# nrf5340_network register map
Vendor: Nordic Semiconductor; Series: nrf53; File version: 1
CPU: CM33 r0p4, little endian, MPU, no FPU, 3 interrupt priority bits, 30 interrupts
Registers are 32-bit, read-write, reset 0x0 unless marked. A register's access mark holds for its fields unless they carry their own. Offsets are from the block's base; [hi:lo] are bit positions; lines under a group give offsets from that group; {n}, {i} and the like mark numbered series; 'fields as' and 'values as' point back to an identical list.

## RADIO_NS — 2.4 GHz radio
Base 0x41008000
0x00 TASKS_TXEN wo — Enable RADIO in TX mode
  [0] TASKS_TXEN
    1=Trigger task
0x04 TASKS_RXEN wo — Enable RADIO in RX mode
  [0] TASKS_RXEN
    1=Trigger task
0x08 TASKS_START wo — Start RADIO
  [0] TASKS_START
    1=Trigger task
0x0C TASKS_STOP wo — Stop RADIO
  [0] TASKS_STOP
    1=Trigger task
0x10 TASKS_DISABLE wo — Disable RADIO
  [0] TASKS_DISABLE
    1=Trigger task
0x14 TASKS_RSSISTART wo — Start the RSSI and take one single sample of the receive signal strength
  [0] TASKS_RSSISTART
    1=Trigger task
0x18 TASKS_RSSISTOP wo — Stop the RSSI measurement
  [0] TASKS_RSSISTOP
    1=Trigger task
0x1C TASKS_BCSTART wo — Start the bit counter
  [0] TASKS_BCSTART
    1=Trigger task
0x20 TASKS_BCSTOP wo — Stop the bit counter
  [0] TASKS_BCSTOP
    1=Trigger task
0x24 TASKS_EDSTART wo — Start the energy detect measurement used in IEEE 802.15.4 mode
  [0] TASKS_EDSTART
    1=Trigger task
0x28 TASKS_EDSTOP wo — Stop the energy detect measurement
  [0] TASKS_EDSTOP
    1=Trigger task
0x2C TASKS_CCASTART wo — Start the clear channel assessment used in IEEE 802.15.4 mode
  [0] TASKS_CCASTART
    1=Trigger task
0x30 TASKS_CCASTOP wo — Stop the clear channel assessment
  [0] TASKS_CCASTOP
    1=Trigger task
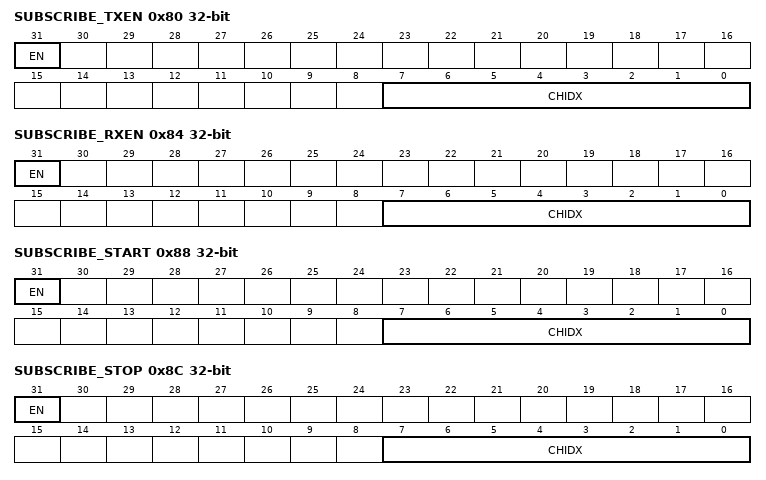
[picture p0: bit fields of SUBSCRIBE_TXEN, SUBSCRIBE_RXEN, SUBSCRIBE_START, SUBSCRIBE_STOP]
0x80 SUBSCRIBE_TXEN — Subscribe configuration for task TXEN
  [31] EN
    0=Disabled (Disable subscription); 1=Enabled (Enable subscription)
  [7:0] CHIDX — DPPI channel that task TXEN will subscribe to
0x84 SUBSCRIBE_RXEN — Subscribe configuration for task RXEN
  [31] EN
    values as SUBSCRIBE_TXEN.EN
  [7:0] CHIDX — DPPI channel that task RXEN will subscribe to
0x88 SUBSCRIBE_START — Subscribe configuration for task START
  [31] EN
    values as SUBSCRIBE_TXEN.EN
  [7:0] CHIDX — DPPI channel that task START will subscribe to
0x8C SUBSCRIBE_STOP — Subscribe configuration for task STOP
  [31] EN
    values as SUBSCRIBE_TXEN.EN
  [7:0] CHIDX — DPPI channel that task STOP will subscribe to
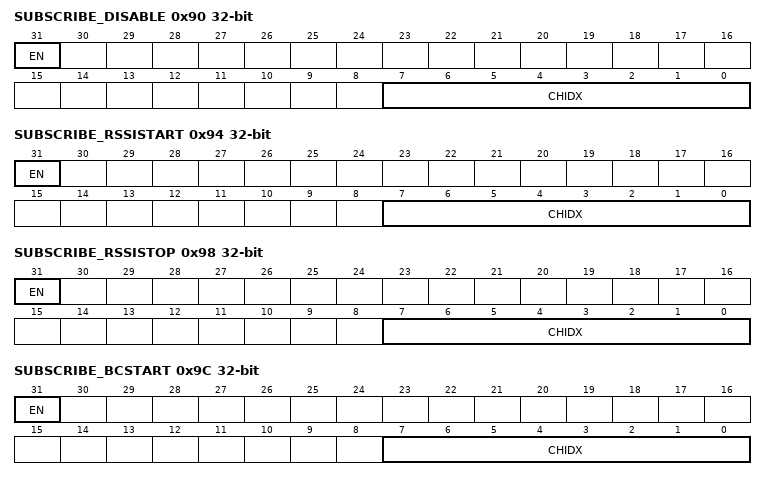
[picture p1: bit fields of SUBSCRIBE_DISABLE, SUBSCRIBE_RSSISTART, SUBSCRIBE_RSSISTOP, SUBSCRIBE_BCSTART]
0x90 SUBSCRIBE_DISABLE — Subscribe configuration for task DISABLE
  [31] EN
    values as SUBSCRIBE_TXEN.EN
  [7:0] CHIDX — DPPI channel that task DISABLE will subscribe to
0x94 SUBSCRIBE_RSSISTART — Subscribe configuration for task RSSISTART
  [31] EN
    values as SUBSCRIBE_TXEN.EN
  [7:0] CHIDX — DPPI channel that task RSSISTART will subscribe to
0x98 SUBSCRIBE_RSSISTOP — Subscribe configuration for task RSSISTOP
  [31] EN
    values as SUBSCRIBE_TXEN.EN
  [7:0] CHIDX — DPPI channel that task RSSISTOP will subscribe to
0x9C SUBSCRIBE_BCSTART — Subscribe configuration for task BCSTART
  [31] EN
    values as SUBSCRIBE_TXEN.EN
  [7:0] CHIDX — DPPI channel that task BCSTART will subscribe to
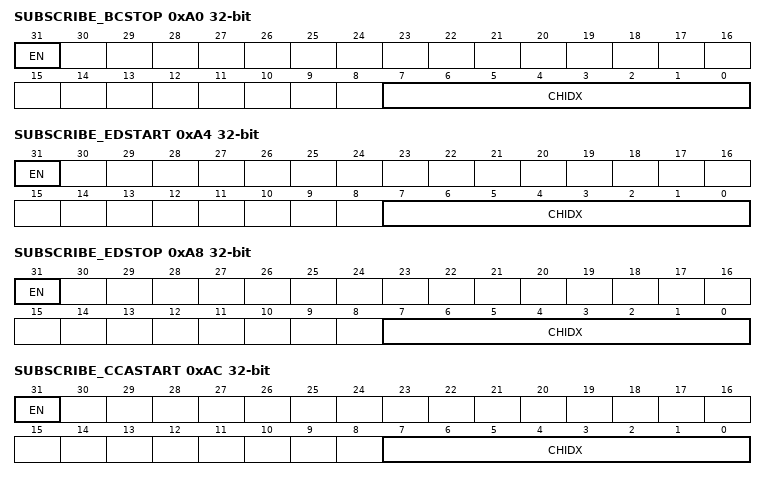
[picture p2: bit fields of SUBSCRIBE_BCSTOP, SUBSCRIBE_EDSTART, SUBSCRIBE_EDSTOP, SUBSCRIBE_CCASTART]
0xA0 SUBSCRIBE_BCSTOP — Subscribe configuration for task BCSTOP
  [31] EN
    values as SUBSCRIBE_TXEN.EN
  [7:0] CHIDX — DPPI channel that task BCSTOP will subscribe to
0xA4 SUBSCRIBE_EDSTART — Subscribe configuration for task EDSTART
  [31] EN
    values as SUBSCRIBE_TXEN.EN
  [7:0] CHIDX — DPPI channel that task EDSTART will subscribe to
0xA8 SUBSCRIBE_EDSTOP — Subscribe configuration for task EDSTOP
  [31] EN
    values as SUBSCRIBE_TXEN.EN
  [7:0] CHIDX — DPPI channel that task EDSTOP will subscribe to
0xAC SUBSCRIBE_CCASTART — Subscribe configuration for task CCASTART
  [31] EN
    values as SUBSCRIBE_TXEN.EN
  [7:0] CHIDX — DPPI channel that task CCASTART will subscribe to
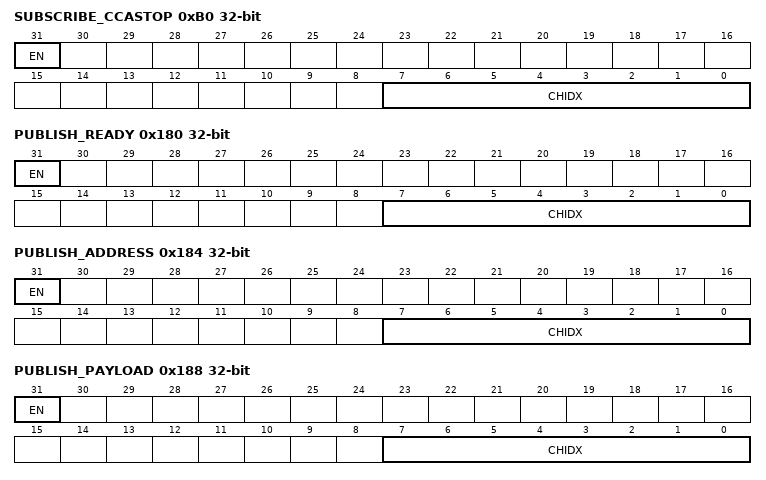
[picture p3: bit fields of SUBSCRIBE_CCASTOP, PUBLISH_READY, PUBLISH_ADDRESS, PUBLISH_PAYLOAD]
0xB0 SUBSCRIBE_CCASTOP — Subscribe configuration for task CCASTOP
  [31] EN
    values as SUBSCRIBE_TXEN.EN
  [7:0] CHIDX — DPPI channel that task CCASTOP will subscribe to
0x100 EVENTS_READY — RADIO has ramped up and is ready to be started
  [0] EVENTS_READY
    0=NotGenerated (Event not generated); 1=Generated (Event generated)
0x104 EVENTS_ADDRESS — Address sent or received
  [0] EVENTS_ADDRESS
    values as EVENTS_READY.EVENTS_READY
0x108 EVENTS_PAYLOAD — Packet payload sent or received
  [0] EVENTS_PAYLOAD
    values as EVENTS_READY.EVENTS_READY
0x10C EVENTS_END — Packet sent or received
  [0] EVENTS_END
    values as EVENTS_READY.EVENTS_READY
0x110 EVENTS_DISABLED — RADIO has been disabled
  [0] EVENTS_DISABLED
    values as EVENTS_READY.EVENTS_READY
0x114 EVENTS_DEVMATCH — A device address match occurred on the last received packet
  [0] EVENTS_DEVMATCH
    values as EVENTS_READY.EVENTS_READY
0x118 EVENTS_DEVMISS — No device address match occurred on the last received packet
  [0] EVENTS_DEVMISS
    values as EVENTS_READY.EVENTS_READY
0x11C EVENTS_RSSIEND — Sampling of receive signal strength complete
  [0] EVENTS_RSSIEND
    values as EVENTS_READY.EVENTS_READY
0x128 EVENTS_BCMATCH — Bit counter reached bit count value
  [0] EVENTS_BCMATCH
    values as EVENTS_READY.EVENTS_READY
0x130 EVENTS_CRCOK — Packet received with CRC ok
  [0] EVENTS_CRCOK
    values as EVENTS_READY.EVENTS_READY
0x134 EVENTS_CRCERROR — Packet received with CRC error
  [0] EVENTS_CRCERROR
    values as EVENTS_READY.EVENTS_READY
0x138 EVENTS_FRAMESTART — IEEE 802.15.4 length field received
  [0] EVENTS_FRAMESTART
    values as EVENTS_READY.EVENTS_READY
0x13C EVENTS_EDEND — Sampling of energy detection complete. A new ED sample is ready for readout from the RADIO.EDSAMPLE register.
  [0] EVENTS_EDEND
    values as EVENTS_READY.EVENTS_READY
0x140 EVENTS_EDSTOPPED — The sampling of energy detection has stopped
  [0] EVENTS_EDSTOPPED
    values as EVENTS_READY.EVENTS_READY
0x144 EVENTS_CCAIDLE — Wireless medium in idle - clear to send
  [0] EVENTS_CCAIDLE
    values as EVENTS_READY.EVENTS_READY
0x148 EVENTS_CCABUSY — Wireless medium busy - do not send
  [0] EVENTS_CCABUSY
    values as EVENTS_READY.EVENTS_READY
0x14C EVENTS_CCASTOPPED — The CCA has stopped
  [0] EVENTS_CCASTOPPED
    values as EVENTS_READY.EVENTS_READY
0x150 EVENTS_RATEBOOST — Ble_LR CI field received, receive mode is changed from Ble_LR125Kbit to Ble_LR500Kbit.
  [0] EVENTS_RATEBOOST
    values as EVENTS_READY.EVENTS_READY
0x154 EVENTS_TXREADY — RADIO has ramped up and is ready to be started TX path
  [0] EVENTS_TXREADY
    values as EVENTS_READY.EVENTS_READY
0x158 EVENTS_RXREADY — RADIO has ramped up and is ready to be started RX path
  [0] EVENTS_RXREADY
    values as EVENTS_READY.EVENTS_READY
0x15C EVENTS_MHRMATCH — MAC header match found
  [0] EVENTS_MHRMATCH
    values as EVENTS_READY.EVENTS_READY
0x168 EVENTS_SYNC — Preamble indicator
  [0] EVENTS_SYNC
    values as EVENTS_READY.EVENTS_READY
0x16C EVENTS_PHYEND — Generated when last bit is sent on air, or received from air
  [0] EVENTS_PHYEND
    values as EVENTS_READY.EVENTS_READY
0x170 EVENTS_CTEPRESENT — CTE is present (early warning right after receiving CTEInfo byte)
  [0] EVENTS_CTEPRESENT
    values as EVENTS_READY.EVENTS_READY
0x180 PUBLISH_READY — Publish configuration for event READY
  [31] EN
    0=Disabled (Disable publishing); 1=Enabled (Enable publishing)
  [7:0] CHIDX — DPPI channel that event READY will publish to.
0x184 PUBLISH_ADDRESS — Publish configuration for event ADDRESS
  [31] EN
    values as PUBLISH_READY.EN
  [7:0] CHIDX — DPPI channel that event ADDRESS will publish to.
0x188 PUBLISH_PAYLOAD — Publish configuration for event PAYLOAD
  [31] EN
    values as PUBLISH_READY.EN
  [7:0] CHIDX — DPPI channel that event PAYLOAD will publish to.
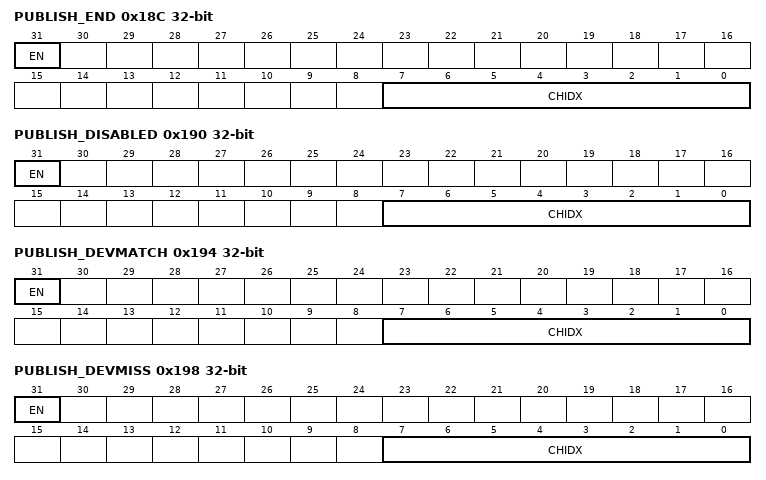
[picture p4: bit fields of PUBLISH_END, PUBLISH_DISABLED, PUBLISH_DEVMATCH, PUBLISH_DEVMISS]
0x18C PUBLISH_END — Publish configuration for event END
  [31] EN
    values as PUBLISH_READY.EN
  [7:0] CHIDX — DPPI channel that event END will publish to.
0x190 PUBLISH_DISABLED — Publish configuration for event DISABLED
  [31] EN
    values as PUBLISH_READY.EN
  [7:0] CHIDX — DPPI channel that event DISABLED will publish to.
0x194 PUBLISH_DEVMATCH — Publish configuration for event DEVMATCH
  [31] EN
    values as PUBLISH_READY.EN
  [7:0] CHIDX — DPPI channel that event DEVMATCH will publish to.
0x198 PUBLISH_DEVMISS — Publish configuration for event DEVMISS
  [31] EN
    values as PUBLISH_READY.EN
  [7:0] CHIDX — DPPI channel that event DEVMISS will publish to.
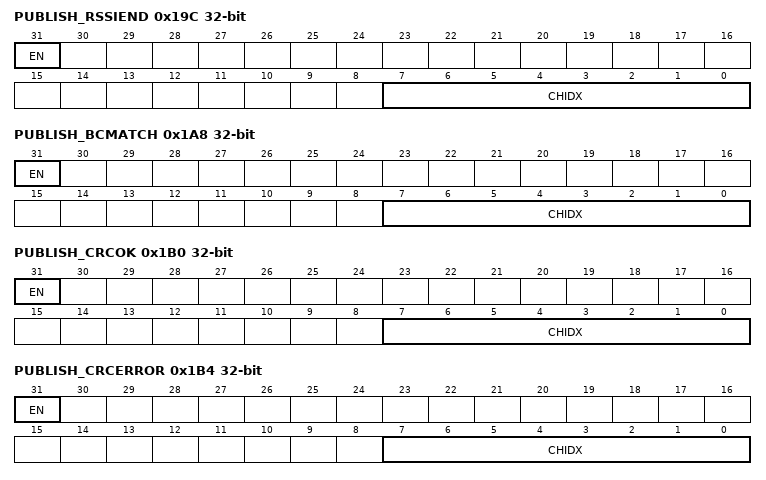
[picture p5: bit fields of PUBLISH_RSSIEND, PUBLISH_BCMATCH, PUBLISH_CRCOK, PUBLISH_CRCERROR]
0x19C PUBLISH_RSSIEND — Publish configuration for event RSSIEND
  [31] EN
    values as PUBLISH_READY.EN
  [7:0] CHIDX — DPPI channel that event RSSIEND will publish to.
0x1A8 PUBLISH_BCMATCH — Publish configuration for event BCMATCH
  [31] EN
    values as PUBLISH_READY.EN
  [7:0] CHIDX — DPPI channel that event BCMATCH will publish to.
0x1B0 PUBLISH_CRCOK — Publish configuration for event CRCOK
  [31] EN
    values as PUBLISH_READY.EN
  [7:0] CHIDX — DPPI channel that event CRCOK will publish to.
0x1B4 PUBLISH_CRCERROR — Publish configuration for event CRCERROR
  [31] EN
    values as PUBLISH_READY.EN
  [7:0] CHIDX — DPPI channel that event CRCERROR will publish to.
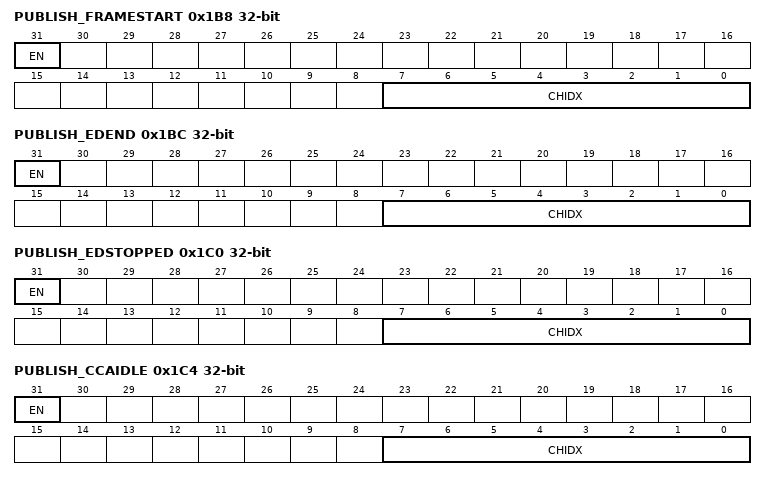
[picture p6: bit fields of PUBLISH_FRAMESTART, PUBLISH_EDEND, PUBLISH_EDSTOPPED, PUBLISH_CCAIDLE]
0x1B8 PUBLISH_FRAMESTART — Publish configuration for event FRAMESTART
  [31] EN
    values as PUBLISH_READY.EN
  [7:0] CHIDX — DPPI channel that event FRAMESTART will publish to.
0x1BC PUBLISH_EDEND — Publish configuration for event EDEND
  [31] EN
    values as PUBLISH_READY.EN
  [7:0] CHIDX — DPPI channel that event EDEND will publish to.
0x1C0 PUBLISH_EDSTOPPED — Publish configuration for event EDSTOPPED
  [31] EN
    values as PUBLISH_READY.EN
  [7:0] CHIDX — DPPI channel that event EDSTOPPED will publish to.
0x1C4 PUBLISH_CCAIDLE — Publish configuration for event CCAIDLE
  [31] EN
    values as PUBLISH_READY.EN
  [7:0] CHIDX — DPPI channel that event CCAIDLE will publish to.
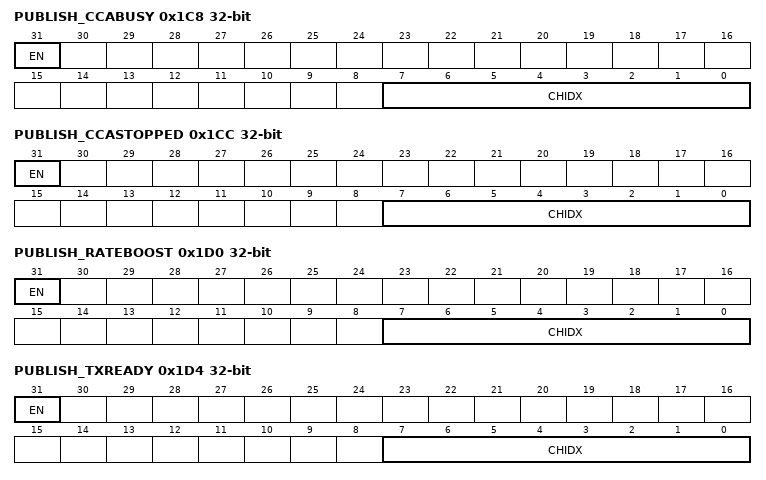
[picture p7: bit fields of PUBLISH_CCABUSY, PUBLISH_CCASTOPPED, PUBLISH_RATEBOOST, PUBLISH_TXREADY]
0x1C8 PUBLISH_CCABUSY — Publish configuration for event CCABUSY
  [31] EN
    values as PUBLISH_READY.EN
  [7:0] CHIDX — DPPI channel that event CCABUSY will publish to.
0x1CC PUBLISH_CCASTOPPED — Publish configuration for event CCASTOPPED
  [31] EN
    values as PUBLISH_READY.EN
  [7:0] CHIDX — DPPI channel that event CCASTOPPED will publish to.
0x1D0 PUBLISH_RATEBOOST — Publish configuration for event RATEBOOST
  [31] EN
    values as PUBLISH_READY.EN
  [7:0] CHIDX — DPPI channel that event RATEBOOST will publish to.
0x1D4 PUBLISH_TXREADY — Publish configuration for event TXREADY
  [31] EN
    values as PUBLISH_READY.EN
  [7:0] CHIDX — DPPI channel that event TXREADY will publish to.
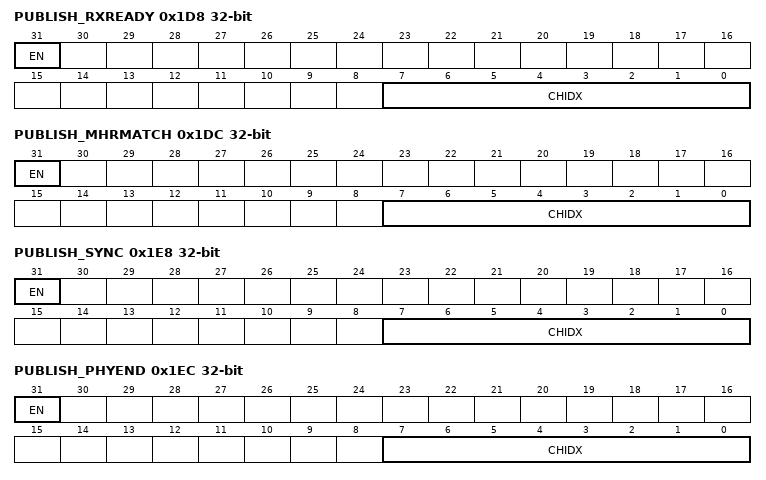
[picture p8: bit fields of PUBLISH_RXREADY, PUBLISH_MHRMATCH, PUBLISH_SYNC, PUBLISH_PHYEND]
0x1D8 PUBLISH_RXREADY — Publish configuration for event RXREADY
  [31] EN
    values as PUBLISH_READY.EN
  [7:0] CHIDX — DPPI channel that event RXREADY will publish to.
0x1DC PUBLISH_MHRMATCH — Publish configuration for event MHRMATCH
  [31] EN
    values as PUBLISH_READY.EN
  [7:0] CHIDX — DPPI channel that event MHRMATCH will publish to.
0x1E8 PUBLISH_SYNC — Publish configuration for event SYNC
  [31] EN
    values as PUBLISH_READY.EN
  [7:0] CHIDX — DPPI channel that event SYNC will publish to.
0x1EC PUBLISH_PHYEND — Publish configuration for event PHYEND
  [31] EN
    values as PUBLISH_READY.EN
  [7:0] CHIDX — DPPI channel that event PHYEND will publish to.
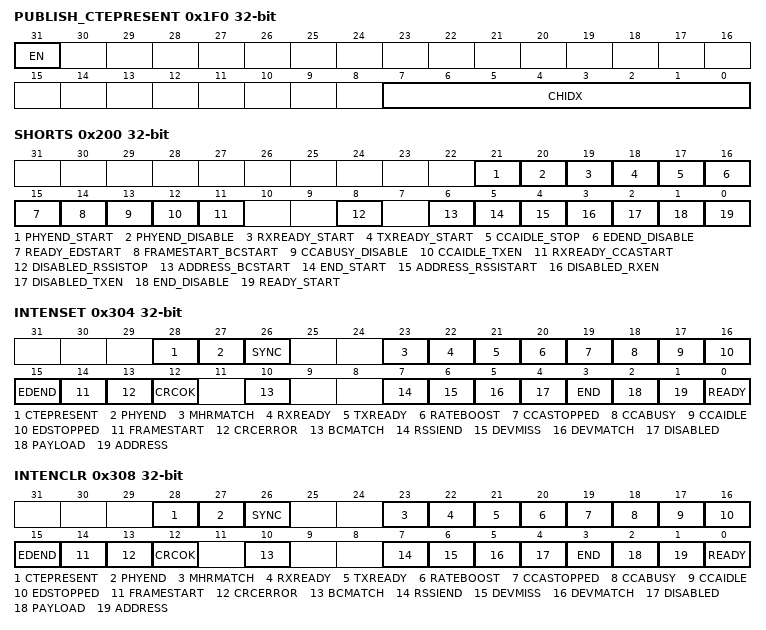
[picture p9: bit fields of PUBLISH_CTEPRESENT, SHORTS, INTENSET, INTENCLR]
0x1F0 PUBLISH_CTEPRESENT — Publish configuration for event CTEPRESENT
  [31] EN
    values as PUBLISH_READY.EN
  [7:0] CHIDX — DPPI channel that event CTEPRESENT will publish to.
0x200 SHORTS — Shortcuts between local events and tasks
  [all] fields
    0=Disabled (Disable shortcut); 1=Enabled (Enable shortcut)
  [21] PHYEND_START — Shortcut between event PHYEND and task START
  [20] PHYEND_DISABLE — Shortcut between event PHYEND and task DISABLE
  [19] RXREADY_START — Shortcut between event RXREADY and task START
  [18] TXREADY_START — Shortcut between event TXREADY and task START
  [17] CCAIDLE_STOP — Shortcut between event CCAIDLE and task STOP
  [16] EDEND_DISABLE — Shortcut between event EDEND and task DISABLE
  [15] READY_EDSTART — Shortcut between event READY and task EDSTART
  [14] FRAMESTART_BCSTART — Shortcut between event FRAMESTART and task BCSTART
  [13] CCABUSY_DISABLE — Shortcut between event CCABUSY and task DISABLE
  [12] CCAIDLE_TXEN — Shortcut between event CCAIDLE and task TXEN
  [11] RXREADY_CCASTART — Shortcut between event RXREADY and task CCASTART
  [8] DISABLED_RSSISTOP — Shortcut between event DISABLED and task RSSISTOP
  [6] ADDRESS_BCSTART — Shortcut between event ADDRESS and task BCSTART
  [5] END_START — Shortcut between event END and task START
  [4] ADDRESS_RSSISTART — Shortcut between event ADDRESS and task RSSISTART
  [3] DISABLED_RXEN — Shortcut between event DISABLED and task RXEN
  [2] DISABLED_TXEN — Shortcut between event DISABLED and task TXEN
  [1] END_DISABLE — Shortcut between event END and task DISABLE
  [0] READY_START — Shortcut between event READY and task START
0x304 INTENSET — Enable interrupt
  [all] fields
    on read: 0=Disabled (Read: Disabled); 1=Enabled (Read: Enabled) | on write: 1=Set (Enable)
  [28] CTEPRESENT — Write '1' to enable interrupt for event CTEPRESENT
  [27] PHYEND — Write '1' to enable interrupt for event PHYEND
  [26] SYNC — Write '1' to enable interrupt for event SYNC
  [23] MHRMATCH — Write '1' to enable interrupt for event MHRMATCH
  [22] RXREADY — Write '1' to enable interrupt for event RXREADY
  [21] TXREADY — Write '1' to enable interrupt for event TXREADY
  [20] RATEBOOST — Write '1' to enable interrupt for event RATEBOOST
  [19] CCASTOPPED — Write '1' to enable interrupt for event CCASTOPPED
  [18] CCABUSY — Write '1' to enable interrupt for event CCABUSY
  [17] CCAIDLE — Write '1' to enable interrupt for event CCAIDLE
  [16] EDSTOPPED — Write '1' to enable interrupt for event EDSTOPPED
  [15] EDEND — Write '1' to enable interrupt for event EDEND
  [14] FRAMESTART — Write '1' to enable interrupt for event FRAMESTART
  [13] CRCERROR — Write '1' to enable interrupt for event CRCERROR
  [12] CRCOK — Write '1' to enable interrupt for event CRCOK
  [10] BCMATCH — Write '1' to enable interrupt for event BCMATCH
  [7] RSSIEND — Write '1' to enable interrupt for event RSSIEND
  [6] DEVMISS — Write '1' to enable interrupt for event DEVMISS
  [5] DEVMATCH — Write '1' to enable interrupt for event DEVMATCH
  [4] DISABLED — Write '1' to enable interrupt for event DISABLED
  [3] END — Write '1' to enable interrupt for event END
  [2] PAYLOAD — Write '1' to enable interrupt for event PAYLOAD
  [1] ADDRESS — Write '1' to enable interrupt for event ADDRESS
  [0] READY — Write '1' to enable interrupt for event READY
0x308 INTENCLR — Disable interrupt
  [all] fields
    on read: 0=Disabled (Read: Disabled); 1=Enabled (Read: Enabled) | on write: 1=Clear (Disable)
  [28] CTEPRESENT — Write '1' to disable interrupt for event CTEPRESENT
  [27] PHYEND — Write '1' to disable interrupt for event PHYEND
  [26] SYNC — Write '1' to disable interrupt for event SYNC
  [23] MHRMATCH — Write '1' to disable interrupt for event MHRMATCH
  [22] RXREADY — Write '1' to disable interrupt for event RXREADY
  [21] TXREADY — Write '1' to disable interrupt for event TXREADY
  [20] RATEBOOST — Write '1' to disable interrupt for event RATEBOOST
  [19] CCASTOPPED — Write '1' to disable interrupt for event CCASTOPPED
  [18] CCABUSY — Write '1' to disable interrupt for event CCABUSY
  [17] CCAIDLE — Write '1' to disable interrupt for event CCAIDLE
  [16] EDSTOPPED — Write '1' to disable interrupt for event EDSTOPPED
  [15] EDEND — Write '1' to disable interrupt for event EDEND
  [14] FRAMESTART — Write '1' to disable interrupt for event FRAMESTART
  [13] CRCERROR — Write '1' to disable interrupt for event CRCERROR
  [12] CRCOK — Write '1' to disable interrupt for event CRCOK
  [10] BCMATCH — Write '1' to disable interrupt for event BCMATCH
  [7] RSSIEND — Write '1' to disable interrupt for event RSSIEND
  [6] DEVMISS — Write '1' to disable interrupt for event DEVMISS
  [5] DEVMATCH — Write '1' to disable interrupt for event DEVMATCH
  [4] DISABLED — Write '1' to disable interrupt for event DISABLED
  [3] END — Write '1' to disable interrupt for event END
  [2] PAYLOAD — Write '1' to disable interrupt for event PAYLOAD
  [1] ADDRESS — Write '1' to disable interrupt for event ADDRESS
  [0] READY — Write '1' to disable interrupt for event READY
0x400 CRCSTATUS ro
  [0] CRCSTATUS — CRC status of packet received
    0=CRCError (Packet received with CRC error); 1=CRCOk (Packet received with CRC ok)
0x408 RXMATCH ro — Received address
  [2:0] RXMATCH
0x40C RXCRC ro — CRC field of previously received packet
  [23:0] RXCRC
0x410 DAI ro — Device address match index
  [2:0] DAI
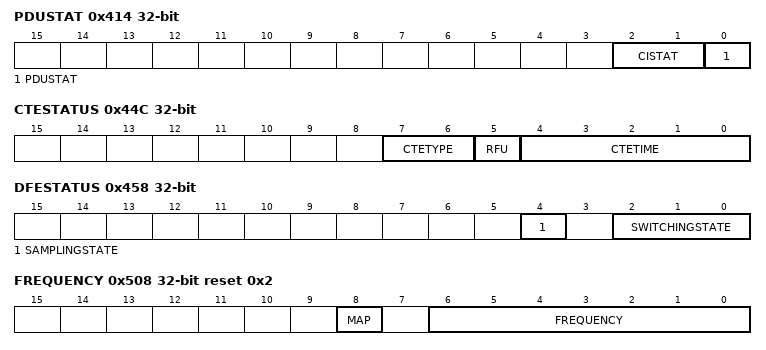
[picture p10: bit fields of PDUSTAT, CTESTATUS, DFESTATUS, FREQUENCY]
0x414 PDUSTAT ro — Payload status
  [2:1] CISTAT — Status on what rate packet is received with in Long Range
    0=LR125kbit (Frame is received at 125 kbps); 1=LR500kbit (Frame is received at 500 kbps)
  [0] PDUSTAT — Status on payload length vs. PCNF1.MAXLEN
    0=LessThan (Payload less than PCNF1.MAXLEN); 1=GreaterThan (Payload greater than PCNF1.MAXLEN)
0x44C CTESTATUS ro — CTEInfo parsed from received packet
  [7:6] CTETYPE — CTEType parsed from packet
  [5] RFU — RFU parsed from packet
  [4:0] CTETIME — CTETime parsed from packet
0x458 DFESTATUS ro — DFE status information
  [4] SAMPLINGSTATE — Internal state of sampling state machine
    0=Idle (Sampling state Idle); 1=Sampling state Sampling
  [2:0] SWITCHINGSTATE — Internal state of switching state machine
    0=Idle (Switching state Idle); 1=Offset (Switching state Offset); 2=Guard (Switching state Guard); 3=Ref (Switching state Ref); 4=Switching state Switching; 5=Ending (Switching state Ending)
0x504 PACKETPTR reset 0x1000000 — Packet pointer
0x508 FREQUENCY reset 0x2
  [8] MAP — Channel map selection
    0=Default (Channel map between 2400 MHz and 2500 MHz); 1=Low (Channel map between 2360 MHz and 2460 MHz)
  [6:0] FREQUENCY — Radio channel frequency
0x50C TXPOWER — Output power
  [7:0] TXPOWER — RADIO output power
    0=0dBm; 255=Neg1dBm (-1 dBm); 254=Neg2dBm (-2 dBm); 253=Neg3dBm (-3 dBm); 252=Neg4dBm (-4 dBm); 251=Neg5dBm (-5 dBm); 250=Neg6dBm (-6 dBm); 249=Neg7dBm (-7 dBm); 248=Neg8dBm (-8 dBm); 244=Neg12dBm (-12 dBm); 240=Neg16dBm (-16 dBm); 236=Neg20dBm (-20 dBm); 226=Neg30dBm (Deprecated enumerator - -40 dBm); 216=Neg40dBm (-40 dBm)
0x510 MODE — Data rate and modulation
  [3:0] MODE — Radio data rate and modulation setting. The radio supports frequency-shift keying (FSK) modulation.
    0=Nrf_1Mbit (1 Mbps Nordic proprietary radio mode); 1=Nrf_2Mbit (2 Mbps Nordic proprietary radio mode); 3=Ble_1Mbit (1 Mbps BLE); 4=Ble_2Mbit (2 Mbps BLE); 5=Ble_LR125Kbit (Long Range 125 kbps TX, 125 kbps and 500 kbps RX); 6=Ble_LR500Kbit (Long Range 500 kbps TX, 125 kbps and 500 kbps RX); 15=Ieee802154_250Kbit (IEEE 802.15.4-2006 250 kbps)
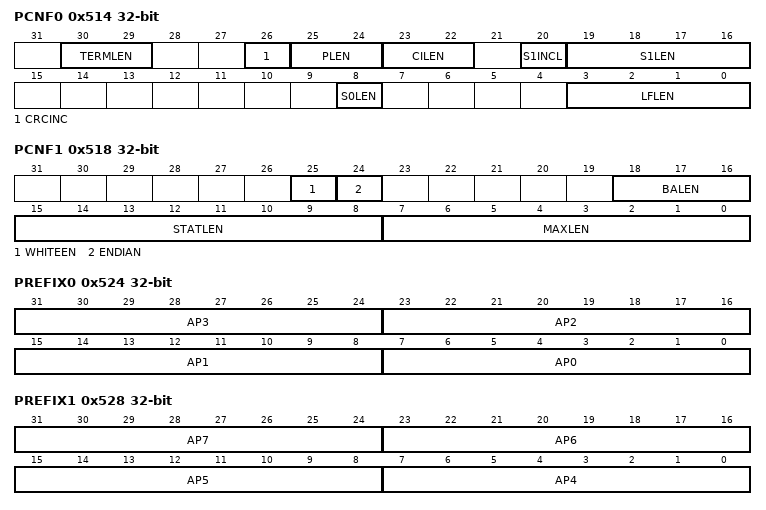
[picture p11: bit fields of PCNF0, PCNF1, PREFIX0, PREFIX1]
0x514 PCNF0 — Packet configuration register 0
  [30:29] TERMLEN — Length of TERM field in Long Range operation
  [26] CRCINC — Indicates if LENGTH field contains CRC or not
    0=Exclude (LENGTH does not contain CRC); 1=Include (LENGTH includes CRC)
  [25:24] PLEN — Length of preamble on air. Decision point: TASKS_START task
    0=8-bit preamble; 1=16-bit preamble; 2=32-bit zero preamble - used for IEEE 802.15.4; 3=LongRange (Preamble - used for Bluetooth LE Long Range)
  [23:22] CILEN — Length of code indicator - Long Range
  [20] S1INCL — Include or exclude S1 field in RAM
    0=Automatic (Include S1 field in RAM only if S1LEN > 0); 1=Include (Always include S1 field in RAM independent of S1LEN)
  [19:16] S1LEN — Length on air of S1 field in number of bits
  [8] S0LEN — Length on air of S0 field in number of bytes
  [3:0] LFLEN — Length on air of LENGTH field in number of bits
0x518 PCNF1 — Packet configuration register 1
  [25] WHITEEN — Enable or disable packet whitening
    0=Disabled; 1=Enabled
  [24] ENDIAN — On-air endianness of packet, this applies to the S0, LENGTH, S1, and the PAYLOAD fields.
    0=Little (Least significant bit on air first); 1=Big (Most significant bit on air first)
  [18:16] BALEN — Base address length in number of bytes
  [15:8] STATLEN — Static length in number of bytes
  [7:0] MAXLEN — Maximum length of packet payload. If the packet payload is larger than MAXLEN, the radio will truncate the payload to MAXLEN.
0x51C BASE0 — Base address 0
0x520 BASE1 — Base address 1
0x524 PREFIX0 — Prefixes bytes for logical addresses 0-3
  [8n+7:8n] AP{n} (n=0..3) — Address prefix {n}.
0x528 PREFIX1 — Prefixes bytes for logical addresses 4-7
  [8n-25:8n-32] AP{n} (n=4..7) — Address prefix {n}.
0x52C TXADDRESS — Transmit address select
  [2:0] TXADDRESS
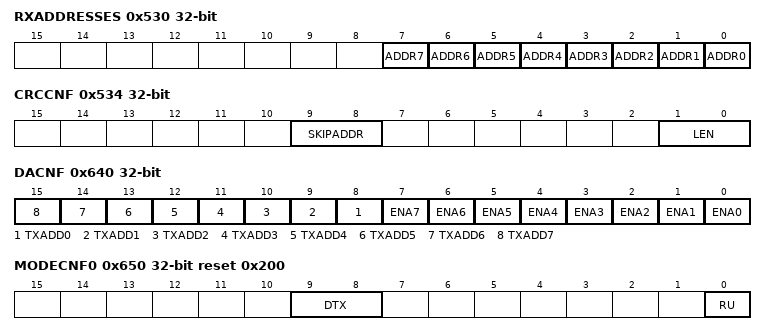
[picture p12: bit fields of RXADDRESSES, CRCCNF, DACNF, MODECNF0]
0x530 RXADDRESSES — Receive address select
  [all] fields
    0=Disabled; 1=Enabled
  [n] ADDR{n} (n=0..7) — Enable or disable reception on logical address {n}.
0x534 CRCCNF — CRC configuration
  [9:8] SKIPADDR — Include or exclude packet address field out of CRC calculation.
    0=Include (CRC calculation includes address field); 1=Skip (CRC calculation does not include address field. The CRC calculation will start at the first byte after the address.); 2=Ieee802154 (CRC calculation as per 802.15.4 standard. Starting at first byte after length field.)
  [1:0] LEN — CRC length in number of bytes For MODE Ble_LR125Kbit and Ble_LR500Kbit, only LEN set to 3 is supported
    0=Disabled (CRC length is zero and CRC calculation is disabled); 1=One (CRC length is one byte and CRC calculation is enabled); 2=Two (CRC length is two bytes and CRC calculation is enabled); 3=Three (CRC length is three bytes and CRC calculation is enabled)
0x538 CRCPOLY — CRC polynomial
  [23:0] CRCPOLY
0x53C CRCINIT — CRC initial value
  [23:0] CRCINIT
0x544 TIFS — Interframe spacing in us
  [9:0] TIFS — Interframe spacing in us.
0x548 RSSISAMPLE ro
  [6:0] RSSISAMPLE
0x550 STATE ro — Current radio state
  [3:0] STATE
    0=Disabled (RADIO is in the Disabled state); 1=RxRu (RADIO is in the RXRU state); 2=RxIdle (RADIO is in the RXIDLE state); 3=Rx (RADIO is in the RX state); 4=RxDisable (RADIO is in the RXDISABLED state); 9=TxRu (RADIO is in the TXRU state); 10=TxIdle (RADIO is in the TXIDLE state); 11=Tx (RADIO is in the TX state); 12=TxDisable (RADIO is in the TXDISABLED state)
0x554 DATAWHITEIV reset 0x40 — Data whitening initial value
  [6:0] DATAWHITEIV — Data whitening initial value. Bit 6 is hardwired to '1', writing '0' to it has no effect, and it will always be read back and used by the device as '1'.
0x560 BCC — Bit counter compare
{0x600+4i} DAB[{i}] (i=0..7) — Description collection: Device address base segment n
  [31:0] DAB — Device address base segment n
{0x620+4i} DAP[{i}] (i=0..7) — Description collection: Device address prefix n
  [15:0] DAP — Device address prefix n
0x640 DACNF — Device address match configuration
  [n+8] TXADD{n} (n=0..7) — TxAdd for device address {n}
  [n] ENA{n} (n=0..7) — Enable or disable device address matching using device address {n}
    0=Disabled; 1=Enabled
0x644 MHRMATCHCONF — Search pattern configuration
0x648 MHRMATCHMAS — Pattern mask
0x650 MODECNF0 reset 0x200 — Radio mode configuration register 0
  [9:8] DTX — Default TX value
    0=B1 (Transmit '1'); 1=B0 (Transmit '0'); 2=Center (Transmit center frequency)
  [0] RU — Radio ramp-up time
    0=Default ramp-up time (tRXEN and tTXEN), compatible with firmware written for nRF51; 1=Fast ramp-up (tRXEN,FAST and tTXEN,FAST), see electrical specifications for more information
0x660 SFD reset 0xA7 — IEEE 802.15.4 start of frame delimiter
  [7:0] SFD
0x664 EDCNT — IEEE 802.15.4 energy detect loop count
  [20:0] EDCNT
0x668 EDSAMPLE ro — IEEE 802.15.4 energy detect level
  [7:0] EDLVL
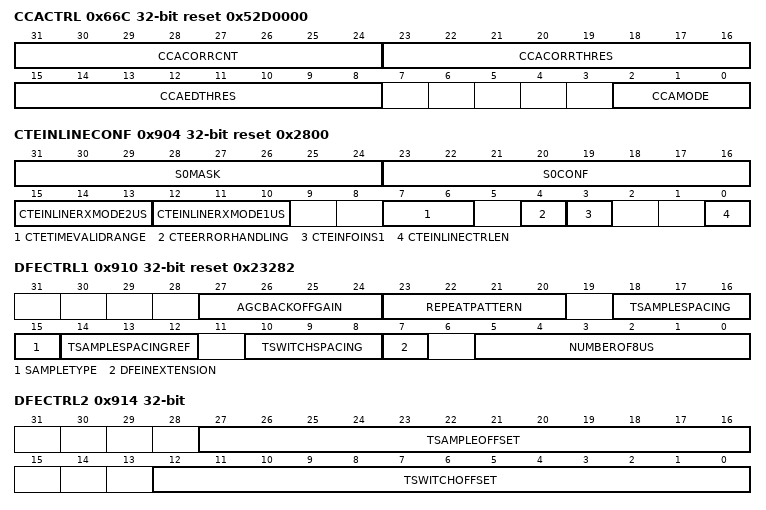
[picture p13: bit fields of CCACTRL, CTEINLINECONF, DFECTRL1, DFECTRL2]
0x66C CCACTRL reset 0x52D0000 — IEEE 802.15.4 clear channel assessment control
  [31:24] CCACORRCNT — Limit for occurances above CCACORRTHRES. When not equal to zero the corrolator based signal detect is enabled.
  [23:16] CCACORRTHRES — CCA correlator busy threshold. Only relevant to CarrierMode, CarrierAndEdMode, and CarrierOrEdMode.
  [15:8] CCAEDTHRES — CCA energy busy threshold. Used in all the CCA modes except CarrierMode.
  [2:0] CCAMODE — CCA mode of operation
    0=EdMode (Energy above threshold); 1=CarrierMode (Carrier seen); 2=CarrierAndEdMode (Energy above threshold AND carrier seen); 3=CarrierOrEdMode (Energy above threshold OR carrier seen); 4=EdModeTest1 (Energy above threshold test mode that will abort when first ED measurement over threshold is seen. No averaging.)
0x900 DFEMODE — Whether to use Angle-of-Arrival (AOA) or Angle-of-Departure (AOD)
  [1:0] DFEOPMODE — Direction finding operation mode
    0=Disabled (Direction finding mode disabled); 2=AoD (Direction finding mode set to AoD); 3=AoA (Direction finding mode set to AoA)
0x904 CTEINLINECONF reset 0x2800 — Configuration for CTE inline mode
  [31:24] S0MASK — S0 bit mask to set which bit to match
  [23:16] S0CONF — S0 bit pattern to match
  [15:13] CTEINLINERXMODE2US — Spacing between samples for the samples in the SWITCHING period when CTEINLINEMODE is set.
    1=4us; 2=2us; 3=1us; 4=500ns (0.5 us); 5=250ns (0.25 us); 6=125ns (0.125 us)
  [12:10] CTEINLINERXMODE1US — Spacing between samples for the samples in the SWITCHING period when CTEINLINEMODE is set.
    values as CTEINLINERXMODE2US
  [7:6] CTETIMEVALIDRANGE — Max range of CTETime
    0=20 in 8 us unit (default) Set to 20 if parsed CTETime is larger than 20; 1=31 in 8 us unit; 2=63 in 8 us unit
  [4] CTEERRORHANDLING — Sampling/switching if CRC is not OK
    1=Yes (Sampling and antenna switching also when CRC is not OK); 0=No (No sampling and antenna switching when CRC is not OK)
  [3] CTEINFOINS1 — CTEInfo is S1 byte or not
    1=InS1 (CTEInfo is in S1 byte (data PDU)); 0=NotInS1 (CTEInfo is NOT in S1 byte (advertising PDU))
  [0] CTEINLINECTRLEN — Enable parsing of CTEInfo from received packet in BLE modes
    1=Enabled (Parsing of CTEInfo is enabled); 0=Disabled (Parsing of CTEInfo is disabled)
0x910 DFECTRL1 reset 0x23282 — Various configuration for Direction finding
  [27:24] AGCBACKOFFGAIN — Gain will be lowered by the specified number of gain steps at the start of CTE
  [23:20] REPEATPATTERN — Repeat each individual antenna pattern N times sequentially, i.e. P0, P0, P1, P1, P2, P2, P3, P3, etc.
    0=NoRepeat (Do not repeat (1 time in total))
  [18:16] TSAMPLESPACING — Interval between samples in the SWITCHING period when CTEINLINECTRLEN is 0
    values as CTEINLINECONF.CTEINLINERXMODE2US
  [15] SAMPLETYPE — Whether to sample I/Q or magnitude/phase
    0=IQ (Complex samples in I and Q); 1=MagPhase (Complex samples as magnitude and phase)
  [14:12] TSAMPLESPACINGREF — Interval between samples in the REFERENCE period
    values as CTEINLINECONF.CTEINLINERXMODE2US
  [10:8] TSWITCHSPACING — Interval between every time the antenna is changed in the SWITCHING state
    1=4us; 2=2us; 3=1us
  [7] DFEINEXTENSION — Add CTE extension and do antenna switching/sampling in this extension
    1=CRC (AoA/AoD procedure triggered at end of CRC); 0=Payload (Antenna switching/sampling is done in the packet payload)
  [5:0] NUMBEROF8US — Length of the AoA/AoD procedure in number of 8 us units
0x914 DFECTRL2 — Start offset for Direction finding
  [27:16] TSAMPLEOFFSET — Signed value offset in number of 16 MHz clock cycles for fine tuning of the sampling instant for all IQ samples. With TSAMPLEOFFSET=0 the first sample is taken immediately at the start of the reference period
  [12:0] TSWITCHOFFSET — Signed value offset after the end of the CRC before starting switching in number of 16 MHz clock cycles
0x928 SWITCHPATTERN — GPIO patterns to be used for each antenna
  [7:0] SWITCHPATTERN — Fill array of GPIO patterns for antenna control.
0x92C CLEARPATTERN — Clear the GPIO pattern array for antenna control
  [0] CLEARPATTERN write-1-clears — Clears GPIO pattern array for antenna control
    1=Clear the GPIO pattern
0x930 PSEL group — Unspecified
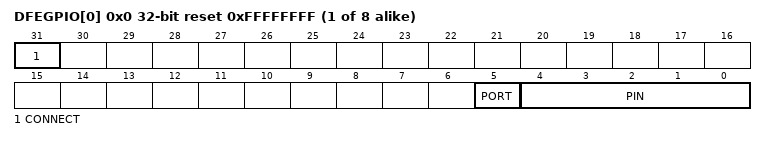
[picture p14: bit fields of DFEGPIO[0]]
  {0x0+4j} DFEGPIO[{j}] (j=0..7) reset 0xFFFFFFFF — Description collection: Pin select for DFE pin n
    [31] CONNECT — Connection
      1=Disconnected; 0=Connected
    [5] PORT — Port number
    [4:0] PIN — Pin number
0x950 DFEPACKET group — DFE packet EasyDMA channel
  0x00 PTR reset 0x1000000 — Data pointer
  0x04 MAXCNT reset 0x1000 — Maximum number of buffer words to transfer
    [13:0] MAXCNT
  0x08 AMOUNT ro — Number of samples transferred in the last transaction
    [15:0] AMOUNT
0xFFC POWER reset 0x1 — Peripheral power control
  [0] POWER — Peripheral power control. The peripheral and its registers will be reset to its initial state by switching the peripheral off and then back on again.
    0=Disabled (Peripheral is powered off); 1=Enabled (Peripheral is powered on)

## Notices in the file
Copyright (c) 2010 - 2021, Nordic Semiconductor ASA All rights reserved.
Redistribution and use in source and binary forms, with or without
modification, are permitted provided that the following conditions are met:
1. Redistributions of source code must retain the above copyright notice, this
list of conditions and the following disclaimer.
2. Redistributions in binary form must reproduce the above copyright
notice, this list of conditions and the following disclaimer in the
documentation and/or other materials provided with the distribution.
3. Neither the name of Nordic Semiconductor ASA nor the names of its
contributors may be used to endorse or promote products derived from this
software without specific prior written permission.
THIS SOFTWARE IS PROVIDED BY THE COPYRIGHT HOLDERS AND CONTRIBUTORS "AS IS"
AND ANY EXPRESS OR IMPLIED WARRANTIES, INCLUDING, BUT NOT LIMITED TO, THE
IMPLIED WARRANTIES OF MERCHANTABILITY, AND FITNESS FOR A PARTICULAR PURPOSE
ARE DISCLAIMED. IN NO EVENT SHALL NORDIC SEMICONDUCTOR ASA OR CONTRIBUTORS BE
LIABLE FOR ANY DIRECT, INDIRECT, INCIDENTAL, SPECIAL, EXEMPLARY, OR
CONSEQUENTIAL DAMAGES (INCLUDING, BUT NOT LIMITED TO, PROCUREMENT OF
SUBSTITUTE GOODS OR SERVICES; LOSS OF USE, DATA, OR PROFITS; OR BUSINESS
INTERRUPTION) HOWEVER CAUSED AND ON ANY THEORY OF LIABILITY, WHETHER IN
CONTRACT, STRICT LIABILITY, OR TORT (INCLUDING NEGLIGENCE OR OTHERWISE)
ARISING IN ANY WAY OUT OF THE USE OF THIS SOFTWARE, EVEN IF ADVISED OF THE
POSSIBILITY OF SUCH DAMAGE.
